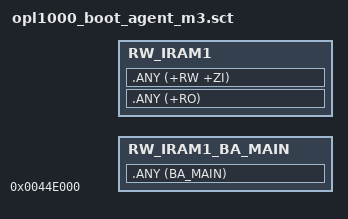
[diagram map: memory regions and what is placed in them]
; *************************************************************
; *** Scatter-Loading Description File generated by uVision ***
; *************************************************************

LR_IROM1 0x0044E000 0x00001000  {    ; load region size_region
    RW_IRAM1_BA_MAIN +0
    {
        .ANY (BA_MAIN)
    }
    RW_IRAM1 +0 
    {
       .ANY (+RO)
       .ANY (+RW +ZI)
    }
}
